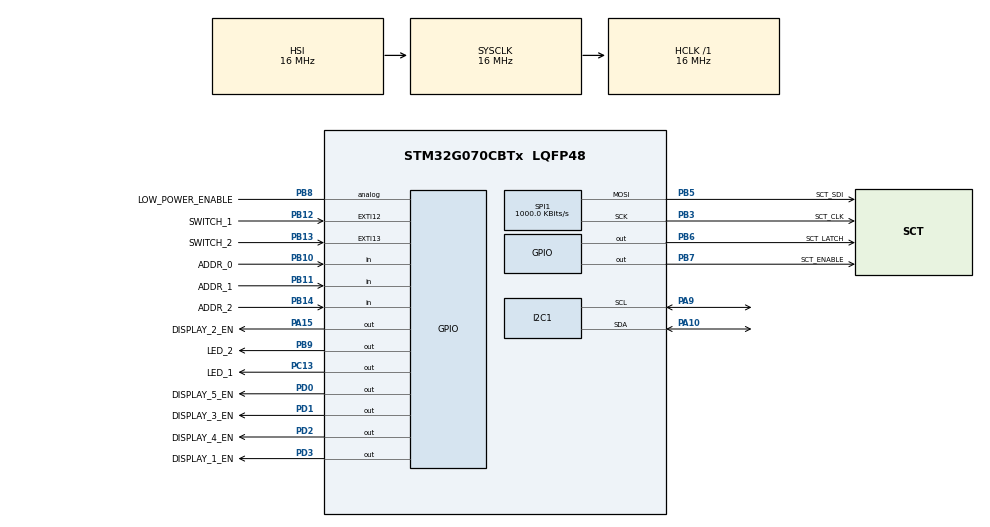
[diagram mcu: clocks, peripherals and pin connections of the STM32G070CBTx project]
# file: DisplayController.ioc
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Dma.Request0=SPI1_TX
Dma.SPI1_TX.0.Direction=DMA_MEMORY_TO_PERIPH
Dma.SPI1_TX.0.EventEnable=DISABLE
Dma.SPI1_TX.0.Instance=DMA1_Channel1
Dma.SPI1_TX.0.MemDataAlignment=DMA_MDATAALIGN_BYTE
Dma.SPI1_TX.0.MemInc=DMA_MINC_ENABLE
Dma.SPI1_TX.0.Mode=DMA_NORMAL
Dma.SPI1_TX.0.PeriphDataAlignment=DMA_PDATAALIGN_BYTE
Dma.SPI1_TX.0.PeriphInc=DMA_PINC_DISABLE
Dma.SPI1_TX.0.Polarity=HAL_DMAMUX_REQ_GEN_RISING
Dma.SPI1_TX.0.Priority=DMA_PRIORITY_HIGH
Dma.SPI1_TX.0.RequestNumber=1
Dma.SPI1_TX.0.SignalID=NONE
Dma.SPI1_TX.0.SyncEnable=DISABLE
Dma.SPI1_TX.0.SyncPolarity=HAL_DMAMUX_SYNC_NO_EVENT
Dma.SPI1_TX.0.SyncRequestNumber=1
Dma.SPI1_TX.0.SyncSignalID=NONE
FREERTOS.Tasks01=defaultTask,24,128,StartDefaultTask,Default,NULL,Dynamic,NULL,NULL
FREERTOS.configUSE_NEWLIB_REENTRANT=1
I2C1.OwnAddress=16
I2C1.Timing=0x00503D58
Mcu.Family=STM32G0
Mcu.Name=STM32G070CBTx
Mcu.Package=LQFP48
NVIC.DMA1_Channel1_IRQn=true\:3\:0\:false\:false\:true\:true\:false\:true\:true
NVIC.EXTI4_15_IRQn=true\:3\:0\:false\:false\:true\:true\:true\:true\:true
NVIC.I2C1_IRQn=true\:1\:0\:false\:false\:true\:true\:true\:true\:true
NVIC.TIM1_BRK_UP_TRG_COM_IRQn=true\:3\:0\:false\:false\:true\:false\:false\:true\:true
NVIC.TIM6_IRQn=true\:3\:0\:false\:false\:true\:true\:true\:true\:true
NVIC.TimeBase=TIM1_BRK_UP_TRG_COM_IRQn
NVIC.TimeBaseIP=TIM1
PA10.Mode=I2C
PA10.Signal=I2C1_SDA
PA13.Mode=Serial_Wire
PA13.Signal=SYS_SWDIO
PA14-BOOT0.Mode=Serial_Wire
PA14-BOOT0.Signal=SYS_SWCLK
PA15.GPIO_Label=DISPLAY_2_EN
PA15.PinState=GPIO_PIN_SET
PA15.Signal=GPIO_Output
PA9.Mode=I2C
PA9.Signal=I2C1_SCL
PB10.GPIO_Label=ADDR_0
PB10.GPIO_PuPd=GPIO_PULLDOWN
PB10.Signal=GPIO_Input
PB11.GPIO_Label=ADDR_1
PB11.GPIO_PuPd=GPIO_PULLDOWN
PB11.Signal=GPIO_Input
PB12.GPIO_Label=SWITCH_1
PB12.GPIO_ModeDefaultEXTI=GPIO_MODE_IT_FALLING
PB12.GPIO_PuPd=GPIO_PULLUP
PB12.Signal=GPXTI12
PB13.GPIO_Label=SWITCH_2
PB13.GPIO_ModeDefaultEXTI=GPIO_MODE_IT_FALLING
PB13.GPIO_PuPd=GPIO_PULLUP
PB13.Signal=GPXTI13
PB14.GPIO_Label=ADDR_2
PB14.GPIO_PuPd=GPIO_PULLDOWN
PB14.Signal=GPIO_Input
PB3.GPIO_Label=SCT_CLK
PB3.Mode=TX_Only_Simplex_Unidirect_Master
PB3.Signal=SPI1_SCK
PB5.GPIO_Label=SCT_SDI
PB5.Mode=TX_Only_Simplex_Unidirect_Master
PB5.Signal=SPI1_MOSI
PB6.GPIO_Label=SCT_LATCH
PB6.Signal=GPIO_Output
PB7.GPIO_Label=SCT_ENABLE
PB7.PinState=GPIO_PIN_SET
PB7.Signal=GPIO_Output
PB8.GPIO_Label=LOW_POWER_ENABLE
PB8.Signal=GPIO_Analog
PB9.GPIO_Label=LED_2
PB9.Signal=GPIO_Output
PC13.GPIO_Label=LED_1
PC13.Signal=GPIO_Output
PD0.GPIO_Label=DISPLAY_5_EN
PD0.PinState=GPIO_PIN_SET
PD0.Signal=GPIO_Output
PD1.GPIO_Label=DISPLAY_3_EN
PD1.PinState=GPIO_PIN_SET
PD1.Signal=GPIO_Output
PD2.GPIO_Label=DISPLAY_4_EN
PD2.PinState=GPIO_PIN_SET
PD2.Signal=GPIO_Output
PD3.GPIO_Label=DISPLAY_1_EN
PD3.PinState=GPIO_PIN_SET
PD3.Signal=GPIO_Output
ProjectManager.HeapSize=0x200
ProjectManager.StackSize=0x400
ProjectManager.TargetToolchain=CMake
RCC.AHBFreq_Value=16000000
RCC.CortexFreq_Value=16000000
RCC.EXTERNAL_CLOCK_VALUE=48000
RCC.HCLKFreq_Value=16000000
RCC.HSE_VALUE=8000000
RCC.HSI_VALUE=16000000
RCC.LSE_VALUE=32768
RCC.SYSCLKFreq_VALUE=16000000
RCC.VCOOutputFreq_Value=128000000
SPI1.BaudRatePrescaler=SPI_BAUDRATEPRESCALER_16
SPI1.CalculateBaudRate=1000.0 KBits/s
SPI1.DataSize=SPI_DATASIZE_8BIT
SPI1.Direction=SPI_DIRECTION_2LINES
SPI1.Mode=SPI_MODE_MASTER
SPI1.VirtualType=VM_MASTER
TIM6.Period=3999
TIM6.Prescaler=15
VP_FREERTOS_VS_CMSIS_V2.Mode=CMSIS_V2
VP_SYS_VS_tim1.Mode=TIM1
VP_TIM6_VS_ClockSourceINT.Mode=Enable_Timer
board=custom

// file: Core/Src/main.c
/* USER CODE BEGIN Header */
/**
  ******************************************************************************
  * @file           : main.c
  * @brief          : Main program body
  ******************************************************************************
  * @attention
  *
  * Copyright (c) 2026 STMicroelectronics.
  * All rights reserved.
  *
  * This software is licensed under terms that can be found in the LICENSE file
  * in the root directory of this software component.
  * If no LICENSE file comes with this software, it is provided AS-IS.
  *
  ******************************************************************************
  */
/* USER CODE END Header */
#include "main.h"
#include "cmsis_os.h"

/* USER CODE BEGIN Includes */
#include <DisplayController.hpp>
#include "task.h"
/* USER CODE END Includes */

I2C_HandleTypeDef hi2c1;

SPI_HandleTypeDef hspi1;
DMA_HandleTypeDef hdma_spi1_tx;

TIM_HandleTypeDef htim6;

/* Definitions for defaultTask */
osThreadId_t defaultTaskHandle;
const osThreadAttr_t defaultTask_attributes = {
  .name = "defaultTask",
  .priority = (osPriority_t) osPriorityNormal,
  .stack_size = 128 * 4
};

void SystemClock_Config(void);
static void MX_GPIO_Init(void);
static void MX_DMA_Init(void);
static void MX_SPI1_Init(void);
static void MX_I2C1_Init(void);
static void MX_TIM6_Init(void);
void StartDefaultTask(void *argument);

/* USER CODE BEGIN PFP */
/* Display refresh tick, from Common/Src/Display/PcbDisplayBoard.cpp. */
void Display_PcbTimerElapsed(TIM_HandleTypeDef* timer);
/* USER CODE END PFP */

int main(void)
{

  /* MCU Configuration--------------------------------------------------------*/

  /* Reset of all peripherals, Initializes the Flash interface and the Systick. */
  HAL_Init();

  /* Configure the system clock */
  SystemClock_Config();

  /* Initialize all configured peripherals */
  MX_GPIO_Init();
  MX_DMA_Init();
  MX_SPI1_Init();
  MX_I2C1_Init();
  MX_TIM6_Init();

  /* Init scheduler */
  osKernelInitialize();

  /* Create the thread(s) */
  /* creation of defaultTask */
  defaultTaskHandle = osThreadNew(StartDefaultTask, NULL, &defaultTask_attributes);

  /* USER CODE BEGIN RTOS_THREADS */
  DisplayController_Init();
  /* USER CODE END RTOS_THREADS */

  /* Start scheduler */
  osKernelStart();

  /* We should never get here as control is now taken by the scheduler */

  /* Infinite loop */
  while (1)
  {

  }
}

void SystemClock_Config(void)
{
  RCC_OscInitTypeDef RCC_OscInitStruct = {0};
  RCC_ClkInitTypeDef RCC_ClkInitStruct = {0};

  /** Configure the main internal regulator output voltage
  */
  HAL_PWREx_ControlVoltageScaling(PWR_REGULATOR_VOLTAGE_SCALE1);

  /** Initializes the RCC Oscillators according to the specified parameters
  * in the RCC_OscInitTypeDef structure.
  */
  RCC_OscInitStruct.OscillatorType = RCC_OSCILLATORTYPE_HSI;
  RCC_OscInitStruct.HSIState = RCC_HSI_ON;
  RCC_OscInitStruct.HSIDiv = RCC_HSI_DIV1;
  RCC_OscInitStruct.HSICalibrationValue = RCC_HSICALIBRATION_DEFAULT;
  RCC_OscInitStruct.PLL.PLLState = RCC_PLL_NONE;
  if (HAL_RCC_OscConfig(&RCC_OscInitStruct) != HAL_OK)
  {
    Error_Handler();
  }

  /** Initializes the CPU, AHB and APB buses clocks
  */
  RCC_ClkInitStruct.ClockType = RCC_CLOCKTYPE_HCLK|RCC_CLOCKTYPE_SYSCLK
                              |RCC_CLOCKTYPE_PCLK1;
  RCC_ClkInitStruct.SYSCLKSource = RCC_SYSCLKSOURCE_HSI;
  RCC_ClkInitStruct.AHBCLKDivider = RCC_SYSCLK_DIV1;
  RCC_ClkInitStruct.APB1CLKDivider = RCC_HCLK_DIV1;

  if (HAL_RCC_ClockConfig(&RCC_ClkInitStruct, FLASH_LATENCY_0) != HAL_OK)
  {
    Error_Handler();
  }
}

static void MX_I2C1_Init(void)
{

  hi2c1.Instance = I2C1;
  hi2c1.Init.Timing = 0x00503D58;
  hi2c1.Init.OwnAddress1 = 32;
  hi2c1.Init.AddressingMode = I2C_ADDRESSINGMODE_7BIT;
  hi2c1.Init.DualAddressMode = I2C_DUALADDRESS_DISABLE;
  hi2c1.Init.OwnAddress2 = 0;
  hi2c1.Init.OwnAddress2Masks = I2C_OA2_NOMASK;
  hi2c1.Init.GeneralCallMode = I2C_GENERALCALL_DISABLE;
  hi2c1.Init.NoStretchMode = I2C_NOSTRETCH_DISABLE;
  if (HAL_I2C_Init(&hi2c1) != HAL_OK)
  {
    Error_Handler();
  }

  /** Configure Analogue filter
  */
  if (HAL_I2CEx_ConfigAnalogFilter(&hi2c1, I2C_ANALOGFILTER_ENABLE) != HAL_OK)
  {
    Error_Handler();
  }

  /** Configure Digital filter
  */
  if (HAL_I2CEx_ConfigDigitalFilter(&hi2c1, 0) != HAL_OK)
  {
    Error_Handler();
  }

}

static void MX_SPI1_Init(void)
{

  /* SPI1 parameter configuration*/
  hspi1.Instance = SPI1;
  hspi1.Init.Mode = SPI_MODE_MASTER;
  hspi1.Init.Direction = SPI_DIRECTION_2LINES;
  hspi1.Init.DataSize = SPI_DATASIZE_8BIT;
  hspi1.Init.CLKPolarity = SPI_POLARITY_LOW;
  hspi1.Init.CLKPhase = SPI_PHASE_1EDGE;
  hspi1.Init.NSS = SPI_NSS_SOFT;
  hspi1.Init.BaudRatePrescaler = SPI_BAUDRATEPRESCALER_16;
  hspi1.Init.FirstBit = SPI_FIRSTBIT_MSB;
  hspi1.Init.TIMode = SPI_TIMODE_DISABLE;
  hspi1.Init.CRCCalculation = SPI_CRCCALCULATION_DISABLE;
  hspi1.Init.CRCPolynomial = 7;
  hspi1.Init.CRCLength = SPI_CRC_LENGTH_DATASIZE;
  hspi1.Init.NSSPMode = SPI_NSS_PULSE_ENABLE;
  if (HAL_SPI_Init(&hspi1) != HAL_OK)
  {
    Error_Handler();
  }

}

static void MX_TIM6_Init(void)
{

  TIM_MasterConfigTypeDef sMasterConfig = {0};

  htim6.Instance = TIM6;
  htim6.Init.Prescaler = 15;
  htim6.Init.CounterMode = TIM_COUNTERMODE_UP;
  htim6.Init.Period = 3999;
  htim6.Init.AutoReloadPreload = TIM_AUTORELOAD_PRELOAD_DISABLE;
  if (HAL_TIM_Base_Init(&htim6) != HAL_OK)
  {
    Error_Handler();
  }
  sMasterConfig.MasterOutputTrigger = TIM_TRGO_RESET;
  sMasterConfig.MasterSlaveMode = TIM_MASTERSLAVEMODE_DISABLE;
  if (HAL_TIMEx_MasterConfigSynchronization(&htim6, &sMasterConfig) != HAL_OK)
  {
    Error_Handler();
  }

}

static void MX_DMA_Init(void)
{

  /* DMA controller clock enable */
  __HAL_RCC_DMA1_CLK_ENABLE();

  /* DMA interrupt init */
  /* DMA1_Channel1_IRQn interrupt configuration */
  HAL_NVIC_SetPriority(DMA1_Channel1_IRQn, 3, 0);
  HAL_NVIC_EnableIRQ(DMA1_Channel1_IRQn);

}

static void MX_GPIO_Init(void)
{
  GPIO_InitTypeDef GPIO_InitStruct = {0};

  /* GPIO Ports Clock Enable */
  __HAL_RCC_GPIOC_CLK_ENABLE();
  __HAL_RCC_GPIOB_CLK_ENABLE();
  __HAL_RCC_GPIOA_CLK_ENABLE();
  __HAL_RCC_GPIOD_CLK_ENABLE();

  /*Configure GPIO pin Output Level */
  HAL_GPIO_WritePin(LED_1_GPIO_Port, LED_1_Pin, GPIO_PIN_RESET);

  /*Configure GPIO pin Output Level */
  HAL_GPIO_WritePin(DISPLAY_2_EN_GPIO_Port, DISPLAY_2_EN_Pin, GPIO_PIN_SET);

  /*Configure GPIO pin Output Level */
  HAL_GPIO_WritePin(GPIOD, DISPLAY_5_EN_Pin|DISPLAY_3_EN_Pin|DISPLAY_4_EN_Pin|DISPLAY_1_EN_Pin, GPIO_PIN_SET);

  /*Configure GPIO pin Output Level */
  HAL_GPIO_WritePin(GPIOB, SCT_LATCH_Pin|LED_2_Pin, GPIO_PIN_RESET);

  /*Configure GPIO pin Output Level */
  HAL_GPIO_WritePin(SCT_ENABLE_GPIO_Port, SCT_ENABLE_Pin, GPIO_PIN_SET);

  /*Configure GPIO pin : LED_1_Pin */
  GPIO_InitStruct.Pin = LED_1_Pin;
  GPIO_InitStruct.Mode = GPIO_MODE_OUTPUT_PP;
  GPIO_InitStruct.Pull = GPIO_NOPULL;
  GPIO_InitStruct.Speed = GPIO_SPEED_FREQ_LOW;
  HAL_GPIO_Init(LED_1_GPIO_Port, &GPIO_InitStruct);

  /*Configure GPIO pins : ADDR_0_Pin ADDR_1_Pin ADDR_2_Pin */
  GPIO_InitStruct.Pin = ADDR_0_Pin|ADDR_1_Pin|ADDR_2_Pin;
  GPIO_InitStruct.Mode = GPIO_MODE_INPUT;
  GPIO_InitStruct.Pull = GPIO_PULLDOWN;
  HAL_GPIO_Init(GPIOB, &GPIO_InitStruct);

  /*Configure GPIO pins : SWITCH_1_Pin SWITCH_2_Pin */
  GPIO_InitStruct.Pin = SWITCH_1_Pin|SWITCH_2_Pin;
  GPIO_InitStruct.Mode = GPIO_MODE_IT_FALLING;
  GPIO_InitStruct.Pull = GPIO_PULLUP;
  HAL_GPIO_Init(GPIOB, &GPIO_InitStruct);

  /*Configure GPIO pin : DISPLAY_2_EN_Pin */
  GPIO_InitStruct.Pin = DISPLAY_2_EN_Pin;
  GPIO_InitStruct.Mode = GPIO_MODE_OUTPUT_PP;
  GPIO_InitStruct.Pull = GPIO_NOPULL;
  GPIO_InitStruct.Speed = GPIO_SPEED_FREQ_LOW;
  HAL_GPIO_Init(DISPLAY_2_EN_GPIO_Port, &GPIO_InitStruct);

  /*Configure GPIO pins : DISPLAY_5_EN_Pin DISPLAY_3_EN_Pin DISPLAY_4_EN_Pin DISPLAY_1_EN_Pin */
  GPIO_InitStruct.Pin = DISPLAY_5_EN_Pin|DISPLAY_3_EN_Pin|DISPLAY_4_EN_Pin|DISPLAY_1_EN_Pin;
  GPIO_InitStruct.Mode = GPIO_MODE_OUTPUT_PP;
  GPIO_InitStruct.Pull = GPIO_NOPULL;
  GPIO_InitStruct.Speed = GPIO_SPEED_FREQ_LOW;
  HAL_GPIO_Init(GPIOD, &GPIO_InitStruct);

  /*Configure GPIO pins : SCT_LATCH_Pin SCT_ENABLE_Pin LED_2_Pin */
  GPIO_InitStruct.Pin = SCT_LATCH_Pin|SCT_ENABLE_Pin|LED_2_Pin;
  GPIO_InitStruct.Mode = GPIO_MODE_OUTPUT_PP;
  GPIO_InitStruct.Pull = GPIO_NOPULL;
  GPIO_InitStruct.Speed = GPIO_SPEED_FREQ_LOW;
  HAL_GPIO_Init(GPIOB, &GPIO_InitStruct);

  /*Configure GPIO pin : LOW_POWER_ENABLE_Pin */
  GPIO_InitStruct.Pin = LOW_POWER_ENABLE_Pin;
  GPIO_InitStruct.Mode = GPIO_MODE_ANALOG;
  GPIO_InitStruct.Pull = GPIO_NOPULL;
  HAL_GPIO_Init(LOW_POWER_ENABLE_GPIO_Port, &GPIO_InitStruct);

  /* EXTI interrupt init*/
  HAL_NVIC_SetPriority(EXTI4_15_IRQn, 3, 0);
  HAL_NVIC_EnableIRQ(EXTI4_15_IRQn);

}

/* USER CODE BEGIN 4 */
/* Name of the task that overflowed its stack; read it with a debugger. */
volatile const char* g_stackOverflowTaskName = 0;

void vApplicationStackOverflowHook(TaskHandle_t xTask, signed char *pcTaskName)
{
  (void)xTask;
  g_stackOverflowTaskName = (const char*)pcTaskName;
  __disable_irq();
  while (1)
  {
  }
}
/* USER CODE END 4 */

void StartDefaultTask(void *argument)
{
  /* USER CODE BEGIN 5 */
  /* CubeMX will not drop this task and it has nothing to do, so it ends at
     once rather than waking every tick; the idle task frees its stack. */
  osThreadExit();
  /* USER CODE END 5 */
}

void HAL_TIM_PeriodElapsedCallback(TIM_HandleTypeDef *htim)
{
  if (htim->Instance == TIM1)
  {
    HAL_IncTick();
  }
  /* USER CODE BEGIN Callback 1 */
  Display_PcbTimerElapsed(htim);
  /* USER CODE END Callback 1 */
}

void Error_Handler(void)
{
  __disable_irq();
  while (1)
  {
  }
}
